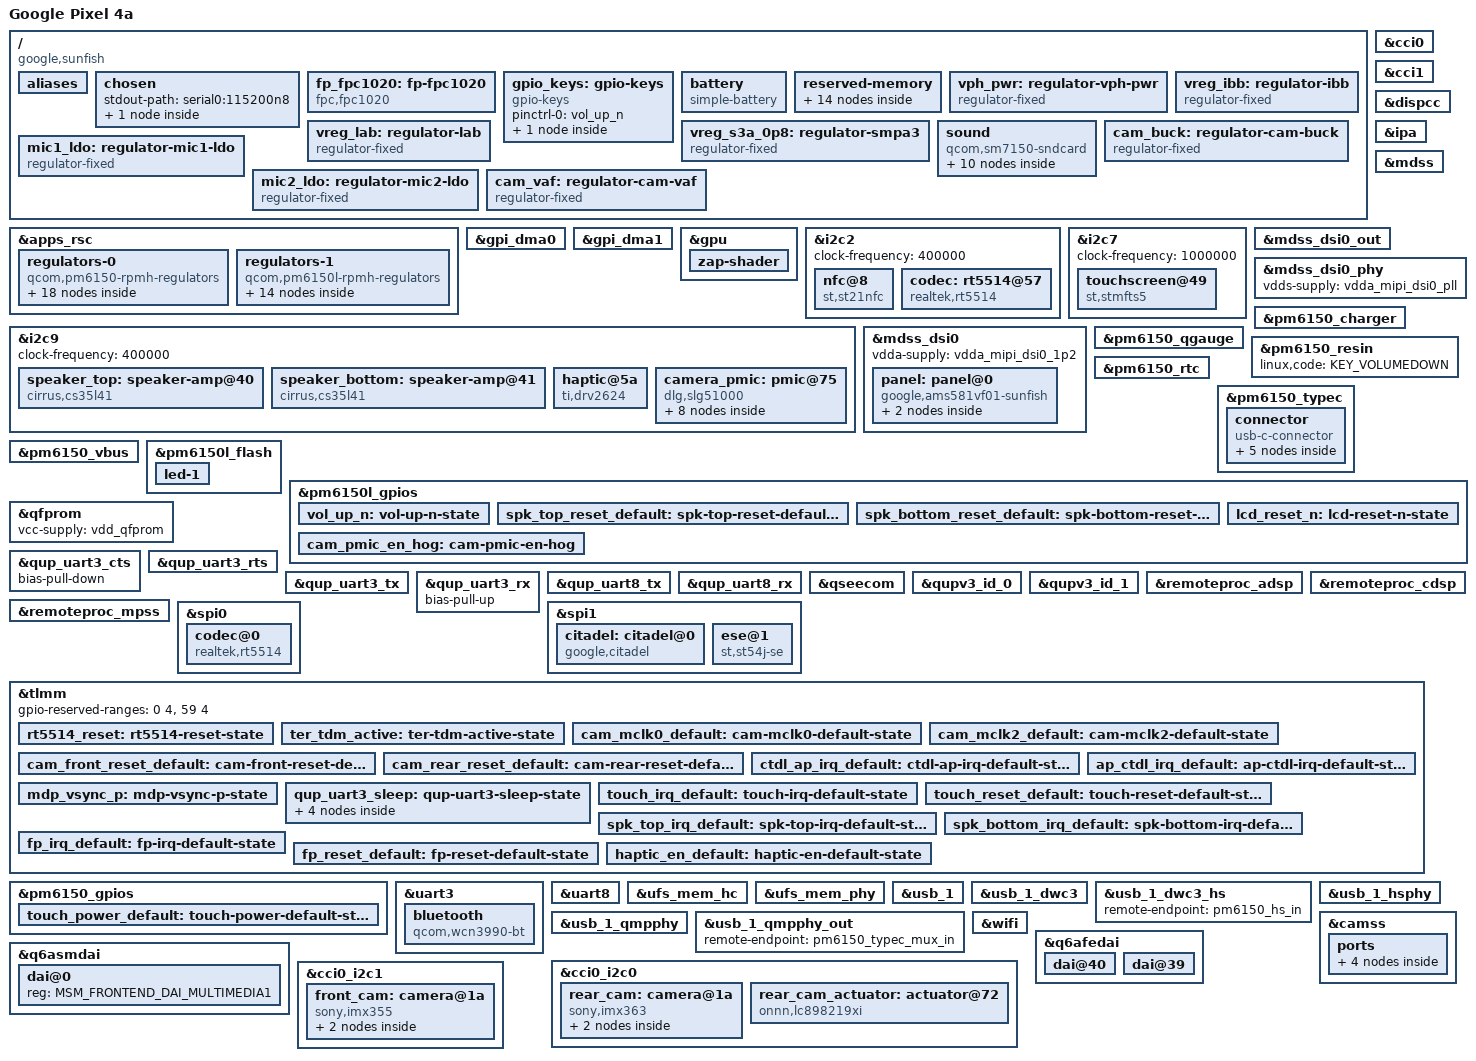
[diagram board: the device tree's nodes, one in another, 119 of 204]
// SPDX-License-Identifier: BSD-3-Clause
/*
 * Copyright (c) 2023-2024, Connor Mitchell <c.dog29@hotmail.com>
 * Copyright (c) 2025, Danila Tikhonov <danila@jiaxyga.com>
 */

/dts-v1/;

#include <dt-bindings/firmware/qcom,scm.h>
#include <dt-bindings/gpio/gpio.h>
#include <dt-bindings/leds/common.h>
#include <dt-bindings/pinctrl/qcom,pmic-gpio.h>
#include <dt-bindings/regulator/qcom,rpmh-regulator.h>
#include <dt-bindings/sound/qcom,q6afe.h>
#include <dt-bindings/sound/qcom,q6asm.h>
#include <dt-bindings/usb/pd.h>

#include "sm7150.dtsi"
#include "pm6150.dtsi"
#include "pm6150l.dtsi"

/delete-node/ &mpss_mem;
/delete-node/ &venus_mem;
/delete-node/ &cdsp_mem;
/delete-node/ &adsp_mem;
/delete-node/ &wlan_msa_mem;
/delete-node/ &npu_mem;
/delete-node/ &ipa_fw_mem;
/delete-node/ &ipa_gsi_mem;
/delete-node/ &gpu_mem;

/ {
	model = "Google Pixel 4a";
	compatible = "google,sunfish", "qcom,sm7150";
	chassis-type = "handset";

	aliases {
		bluetooth0 = &bluetooth;
		hsuart0 = &uart3;
		serial0 = &uart8;
		wifi0 = &wifi;
	};

	chosen {
		#address-cells = <2>;
		#size-cells = <2>;
		ranges;

		stdout-path = "serial0:115200n8";

		framebuffer@9c000000 {
			compatible = "simple-framebuffer";
			reg = <0x0 0x9c000000 0x0 (1080 * 2340 * 4)>;
			width = <1080>;
			height = <2340>;
			stride = <(1080 * 4)>;
			format = "a8r8g8b8";

			clocks = <&gcc GCC_DISP_HF_AXI_CLK>;
		};
	};

	/*
	 * The sensor's SPI bus belongs to the TrustZone fingerprint app;
	 * Linux only drives reset and forwards the interrupt. The vendor
	 * HAL finds the device by looking for "fpc1020" under
	 * /sys/bus/platform/devices, so keep that in the node name.
	 */
	fp_fpc1020: fp-fpc1020 {
		compatible = "fpc,fpc1020";

		irq-gpios = <&tlmm 90 GPIO_ACTIVE_HIGH>;
		reset-gpios = <&tlmm 91 GPIO_ACTIVE_LOW>;

		pinctrl-0 = <&fp_irq_default>, <&fp_reset_default>;
		pinctrl-names = "default";
	};

	gpio_keys: gpio-keys {
		compatible = "gpio-keys";

		pinctrl-0 = <&vol_up_n>;
		pinctrl-names = "default";

		key-volume-up {
			label = "Volume Up";
			gpios = <&pm6150l_gpios 2 GPIO_ACTIVE_LOW>;
			linux,code = <KEY_VOLUMEUP>;
			debounce-interval = <15>;
			linux,can-disable;
			wakeup-source;
		};
	};

	/*
	 * Values match Google's downstream sunfish ATL/LSN cell profiles
	 * (3080 mAh, 4.45 V max, 3.30 V min). The downstream kernel
	 * dynamically selects per-cell profiles via a battery-ID resistor;
	 * the DT-only path here picks the original pack data shared by
	 * both vendors. Phones whose LSN cells received the post-incident
	 * software mitigation (max charge limited to 3.95 V) will see
	 * qcom_qg's voltage-based SOC plateau well below 100 %.
	 */
	battery: battery {
		compatible = "simple-battery";
		voltage-min-design-microvolt = <3300000>;
		voltage-max-design-microvolt = <4450000>;
		charge-full-design-microamp-hours = <3080000>;
		/*
		 * Approximate cell + path resistance; the downstream fuel gauge
		 * measures ESR at runtime instead. Used to estimate the resting
		 * voltage for the OCV lookup while charging or under load.
		 */
		factory-internal-resistance-micro-ohms = <150000>;

		/*
		 * OCV -> state-of-charge tables from Google's downstream ATL
		 * QG profile (batterydata-qcom-s5-SWD-ATL.dtsi,
		 * qcom,pc-temp-v1-lut). The LSN profile differs by < 20 mV,
		 * so one set of tables serves both cell vendors.
		 */
		ocv-capacity-celsius = <0 10 25 40 50>;
		/* 0 degC */
		ocv-capacity-table-0 = <4419500 100>, <4396800 98>, <4373700 96>, <4350900 94>,
			<4327500 92>, <4303000 90>, <4278400 88>, <4253900 86>,
			<4229400 84>, <4205400 82>, <4181900 80>, <4158800 78>,
			<4136300 76>, <4114500 74>, <4093600 72>, <4073500 70>,
			<4053500 68>, <4032800 66>, <4012900 64>, <3996100 62>,
			<3981100 60>, <3965400 58>, <3948900 56>, <3931400 54>,
			<3910900 52>, <3889400 50>, <3873800 48>, <3862300 46>,
			<3853600 44>, <3847400 42>, <3842500 40>, <3837700 38>,
			<3833200 36>, <3829100 34>, <3825500 32>, <3822000 30>,
			<3818500 28>, <3815200 26>, <3810500 24>, <3802200 22>,
			<3791400 20>, <3779200 18>, <3764800 16>, <3748600 14>,
			<3732900 12>, <3721700 10>, <3717800 9>, <3714300 8>,
			<3711200 7>, <3707700 6>, <3693000 5>, <3652700 4>,
			<3595700 3>, <3516900 2>, <3382800 1>, <3000000 0>;
		/* 10 degC */
		ocv-capacity-table-1 = <4430200 100>, <4407100 98>, <4385500 96>, <4363200 94>,
			<4340800 92>, <4317400 90>, <4293000 88>, <4268400 86>,
			<4243700 84>, <4219100 82>, <4195000 80>, <4171200 78>,
			<4148100 76>, <4125600 74>, <4103800 72>, <4082800 70>,
			<4062600 68>, <4042800 66>, <4023600 64>, <4005200 62>,
			<3989000 60>, <3972200 58>, <3948500 56>, <3918500 54>,
			<3897600 52>, <3884700 50>, <3874400 48>, <3865300 46>,
			<3857500 44>, <3849800 42>, <3842600 40>, <3835900 38>,
			<3829900 36>, <3824500 34>, <3820000 32>, <3816000 30>,
			<3812100 28>, <3808600 26>, <3804000 24>, <3795700 22>,
			<3784000 20>, <3771500 18>, <3757400 16>, <3741000 14>,
			<3724800 12>, <3713700 10>, <3710700 9>, <3708700 8>,
			<3706400 7>, <3702900 6>, <3685100 5>, <3643200 4>,
			<3584800 3>, <3504200 2>, <3370300 1>, <3000000 0>;
		/* 25 degC */
		ocv-capacity-table-2 = <4437900 100>, <4412000 98>, <4390000 96>, <4368600 94>,
			<4346300 92>, <4323200 90>, <4299200 88>, <4274400 86>,
			<4249600 84>, <4224900 82>, <4200400 80>, <4176400 78>,
			<4152900 76>, <4129800 74>, <4107300 72>, <4085500 70>,
			<4064700 68>, <4044600 66>, <4025800 64>, <4007800 62>,
			<3990100 60>, <3973200 58>, <3953700 56>, <3926800 54>,
			<3902400 52>, <3888800 50>, <3878700 48>, <3868400 46>,
			<3858100 44>, <3848800 42>, <3840500 40>, <3833100 38>,
			<3826600 36>, <3820800 34>, <3815700 32>, <3811400 30>,
			<3806900 28>, <3802500 26>, <3797400 24>, <3789400 22>,
			<3778200 20>, <3766100 18>, <3752700 16>, <3736700 14>,
			<3719800 12>, <3709300 10>, <3706700 9>, <3705000 8>,
			<3703200 7>, <3699200 6>, <3679300 5>, <3636300 4>,
			<3578400 3>, <3499500 2>, <3377200 1>, <3000000 0>;
		/* 40 degC */
		ocv-capacity-table-3 = <4440600 100>, <4413900 98>, <4391100 96>, <4370100 94>,
			<4348200 92>, <4325900 90>, <4302700 88>, <4278600 86>,
			<4254100 84>, <4229400 82>, <4204700 80>, <4180600 78>,
			<4157000 76>, <4133700 74>, <4111000 72>, <4088900 70>,
			<4067700 68>, <4047300 66>, <4028000 64>, <4009600 62>,
			<3991600 60>, <3974400 58>, <3955700 56>, <3931500 54>,
			<3907600 52>, <3891600 50>, <3879300 48>, <3868000 46>,
			<3857300 44>, <3847400 42>, <3838400 40>, <3830200 38>,
			<3823000 36>, <3816500 34>, <3810700 32>, <3805700 30>,
			<3800400 28>, <3794400 26>, <3787500 24>, <3779100 22>,
			<3768800 20>, <3757300 18>, <3743900 16>, <3728300 14>,
			<3712200 12>, <3702900 10>, <3700600 9>, <3699100 8>,
			<3697300 7>, <3693200 6>, <3671500 5>, <3627800 4>,
			<3570400 3>, <3492300 2>, <3372300 1>, <3000000 0>;
		/* 50 degC */
		ocv-capacity-table-4 = <4441700 100>, <4413900 98>, <4391400 96>, <4370300 94>,
			<4349500 92>, <4327400 90>, <4304400 88>, <4280400 86>,
			<4256000 84>, <4231700 82>, <4207400 80>, <4183300 78>,
			<4159400 76>, <4135900 74>, <4113000 72>, <4090900 70>,
			<4069600 68>, <4049200 66>, <4029700 64>, <4011100 62>,
			<3992800 60>, <3975200 58>, <3956500 56>, <3933200 54>,
			<3909500 52>, <3892700 50>, <3879500 48>, <3867900 46>,
			<3857200 44>, <3847400 42>, <3838100 40>, <3829600 38>,
			<3821900 36>, <3814800 34>, <3808300 32>, <3802600 30>,
			<3796400 28>, <3788800 26>, <3780200 24>, <3771100 22>,
			<3761200 20>, <3749900 18>, <3736400 16>, <3721000 14>,
			<3705400 12>, <3696700 10>, <3694400 9>, <3692900 8>,
			<3691200 7>, <3686100 6>, <3662100 5>, <3617600 4>,
			<3560000 3>, <3481800 2>, <3360700 1>, <3000000 0>;
	};

	reserved-memory {
		mpss_mem: memory@8b000000 {
			reg = <0x0 0x8b000000 0x0 0x9800000>;
			no-map;
		};

		venus_mem: memory@94800000 {
			reg = <0x0 0x94800000 0x0 0x500000>;
			no-map;
		};

		cdsp_mem: memory@94d00000 {
			reg = <0x0 0x94d00000 0x0 0x1e00000>;
			no-map;
		};

		adsp_mem: memory@96b00000 {
			reg = <0x00 0x96b00000 0x00 0x2200000>;
			no-map;
		};

		wlan_msa_mem: memory@98d00000 {
			reg = <0x0 0x98d00000 0x0 0x200000>;
			no-map;
		};

		npu_mem: memory@98f00000 {
			reg = <0x0 0x98f00000 0x0 0x80000>;
			no-map;
		};

		ipa_fw_mem: memory@98f80000 {
			reg = <0x0 0x98f80000 0x0 0x10000>;
			no-map;
		};

		ipa_gsi_mem: memory@98f90000 {
			reg = <0x0 0x98f90000 0x0 0x5000>;
			no-map;
		};

		gpu_mem: memory@98f95000 {
			reg = <0x0 0x98f95000 0x0 0x2000>;
			no-map;
		};

		cont_splash_mem: cont-splash@9c000000 {
			reg = <0x0 0x9c000000 0x0 (1080 * 2340 * 4)>;
			no-map;
		};

		ramoops_mem: ramoops@a481f000 {
			compatible = "ramoops";
			reg = <0x0 0xa481f000 0x0 0x400000>;

			record-size = <0x40000>;
			console-size = <0x200000>;
			pmsg-size = <0x100000>;
		};

		rmtfs_mem: rmtfs@fde01000 {
			compatible = "qcom,rmtfs-mem";
			reg = <0x0 0xfde01000 0x0 0x600000>;
			no-map;

			qcom,client-id = <1>;
			qcom,vmid = <QCOM_SCM_VMID_MSS_MSA>;
		};

		/*
		 * rmtfs is 4K- but not 16K-aligned. With 16K pages the pages at
		 * either end would also hold ordinary RAM, so memremap() of
		 * rmtfs fails. Keep those slivers out of the linear map.
		 */
		rmtfs_pad_lo: memory@fde00000 {
			reg = <0x0 0xfde00000 0x0 0x1000>;
			no-map;
		};

		rmtfs_pad_hi: memory@fe401000 {
			reg = <0x0 0xfe401000 0x0 0x3000>;
			no-map;
		};
	};

	vph_pwr: regulator-vph-pwr {
		compatible = "regulator-fixed";

		regulator-name = "vph_pwr";
		regulator-min-microvolt = <3700000>;
		regulator-max-microvolt = <3700000>;

		regulator-always-on;
		regulator-boot-on;
	};

	vreg_ibb: regulator-ibb {
		compatible = "regulator-fixed";

		regulator-name = "ibb";
		regulator-min-microvolt = <6000000>;
		regulator-max-microvolt = <6000000>;
	};

	vreg_lab: regulator-lab {
		compatible = "regulator-fixed";

		regulator-name = "lab";
		regulator-min-microvolt = <6100000>;
		regulator-max-microvolt = <6100000>;
	};

	// S3A is really mx.lvl but it's there for supply map completeness sake.
	vreg_s3a_0p8: regulator-smpa3 {
		compatible = "regulator-fixed";

		regulator-name = "vreg_s3a_0p8";
		regulator-min-microvolt = <800000>;
		regulator-max-microvolt = <800000>;

		regulator-always-on;
		vin-supply = <&vph_pwr>;
	};
};

&apps_rsc {
	regulators-0 {
		compatible = "qcom,pm6150-rpmh-regulators";
		qcom,pmic-id = "a";

		vdd-s1-supply = <&vph_pwr>;
		vdd-s2-supply = <&vph_pwr>;
		vdd-s3-supply = <&vph_pwr>;
		vdd-s4-supply = <&vph_pwr>;
		vdd-s5-supply = <&vph_pwr>;

		vdd-l1-supply = <&vreg_s8c_1p2>;
		vdd-l2-l3-supply = <&vreg_s4a_1p1>;
		vdd-l4-l7-l8-supply = <&vreg_s4a_1p1>;
		vdd-l5-l16-l17-l18-l19-supply = <&vreg_bob>;
		vdd-l6-supply = <&vreg_s8c_1p2>;
		vdd-l9-supply = <&vreg_s3a_0p8>;
		vdd-l10-l14-l15-supply = <&vreg_s5a_2p0>;
		vdd-l11-l12-l13-supply = <&vreg_s5a_2p0>;

		/*
		 * S1, S4, S5 are unused.
		 * S2-S3 and L7-L8 are ARCs:
		 * S2 - gfx.lvl,
		 * S3 - mx.lvl,
		 * L7 - lmx.lvl,
		 * L8 - lcx.lvl.
		 */

		vreg_s4a_1p1: smps4 {
			regulator-name = "vreg_s4a_1p1";
			regulator-min-microvolt = <824000>;
			regulator-max-microvolt = <1120000>;
			regulator-initial-mode = <RPMH_REGULATOR_MODE_HPM>;
		};

		vreg_s5a_2p0: smps5 {
			regulator-name = "vreg_s5a_2p0";
			regulator-min-microvolt = <1744000>;
			regulator-max-microvolt = <2040000>;
			regulator-initial-mode = <RPMH_REGULATOR_MODE_HPM>;
		};

		vreg_l1a_1p2: ldo1 {
			regulator-name = "vreg_l1a_1p2";
			regulator-min-microvolt = <1096000>;
			regulator-max-microvolt = <1304000>;
			regulator-initial-mode = <RPMH_REGULATOR_MODE_HPM>;
		};

		vreg_l2a_1p0: ldo2 {
			regulator-name = "vreg_l2a_1p0";
			regulator-min-microvolt = <944000>;
			regulator-max-microvolt = <1056000>;
			regulator-initial-mode = <RPMH_REGULATOR_MODE_HPM>;
		};

		vdda_pll_cc_ebi01:
		vreg_l3a_1p0: ldo3 {
			regulator-name = "vreg_l3a_1p0";
			regulator-min-microvolt = <968000>;
			regulator-max-microvolt = <1064000>;
			regulator-initial-mode = <RPMH_REGULATOR_MODE_HPM>;
		};

		vdd_qlink_lv:
		vdd_qlink_lv_ck:
		vdd_usb_hs_core:
		vdda_mipi_csi0_0p9:
		vdda_mipi_csi1_0p9:
		vdda_mipi_csi2_0p9:
		vdda_mipi_csi3_0p9:
		vdda_mipi_dsi0_pll:
		vdda_qrefs_0p9:
		vdda_ufs_core:
		vdda_usb_ss_dp_core:
		vreg_l4a_0p88: ldo4 {
			regulator-name = "vreg_l4a_0p88";
			regulator-min-microvolt = <824000>;
			regulator-max-microvolt = <920000>;
			regulator-initial-mode = <RPMH_REGULATOR_MODE_HPM>;
			regulator-allow-set-load;
			regulator-allowed-modes = <RPMH_REGULATOR_MODE_LPM
						   RPMH_REGULATOR_MODE_HPM>;
		};

		vreg_l5a_2p7: ldo5 {
			regulator-name = "vreg_l5a_2p7";
			regulator-min-microvolt = <2600000>;
			regulator-max-microvolt = <2800000>;
			regulator-initial-mode = <RPMH_REGULATOR_MODE_HPM>;
		};

		vreg_l6a_1p2: ldo6 {
			regulator-name = "vreg_l6a_1p2";
			regulator-min-microvolt = <1096000>;
			regulator-max-microvolt = <1304000>;
			regulator-initial-mode = <RPMH_REGULATOR_MODE_HPM>;
		};

		vdd_wcss_cx:
		vreg_l9a_0p8: ldo9 {
			regulator-name = "vreg_l9a_0p8";
			regulator-min-microvolt = <624000>;
			regulator-max-microvolt = <760000>;
			regulator-initial-mode = <RPMH_REGULATOR_MODE_HPM>;
		};

		vddpx_3:
		vreg_l10a_1p8: ldo10 {
			regulator-name = "vreg_l10a_1p8";
			regulator-min-microvolt = <1720000>;
			regulator-max-microvolt = <1832000>;
			regulator-initial-mode = <RPMH_REGULATOR_MODE_HPM>;
		};

		vdd_qfprom:
		vdda_apc1_cs_1p8:
		vdda_qrefs_1p8:
		vdda_usb_hs_1p8:
		vddpx_11:
		vreg_l11a_1p8: ldo11 {
			regulator-name = "vreg_l11a_1p8";
			regulator-min-microvolt = <1696000>;
			regulator-max-microvolt = <1984000>;
			regulator-initial-mode = <RPMH_REGULATOR_MODE_HPM>;
		};

		vreg_l12a_1p8: ldo12 {
			regulator-name = "vreg_l12a_1p8";
			regulator-min-microvolt = <1696000>;
			regulator-max-microvolt = <1952000>;
			regulator-initial-mode = <RPMH_REGULATOR_MODE_HPM>;
			regulator-allow-set-load;
			regulator-allowed-modes = <RPMH_REGULATOR_MODE_LPM
						   RPMH_REGULATOR_MODE_HPM>;
		};

		vreg_l13a_1p8: ldo13 {
			regulator-name = "vreg_l13a_1p8";
			regulator-min-microvolt = <1696000>;
			regulator-max-microvolt = <1904000>;
			regulator-initial-mode = <RPMH_REGULATOR_MODE_HPM>;
		};

		vreg_l14a_1p8: ldo14 {
			regulator-name = "vreg_l14a_1p8";
			regulator-min-microvolt = <1720000>;
			regulator-max-microvolt = <1856000>;
			regulator-initial-mode = <RPMH_REGULATOR_MODE_HPM>;
		};

		vreg_l15a_1p8: ldo15 {
			regulator-name = "vreg_l15a_1p8";
			regulator-min-microvolt = <1696000>;
			regulator-max-microvolt = <1904000>;
			regulator-initial-mode = <RPMH_REGULATOR_MODE_HPM>;
		};

		vreg_l16a_2p8: ldo16 {
			regulator-name = "vreg_l16a_2p8";
			regulator-min-microvolt = <2424000>;
			regulator-max-microvolt = <2976000>;
			regulator-initial-mode = <RPMH_REGULATOR_MODE_HPM>;
		};

		vdda_usb_hs_3p1:
		vreg_l17a_3p1: ldo17 {
			regulator-name = "vreg_l17a_3p1";
			regulator-min-microvolt = <3000000>;
			regulator-max-microvolt = <3232000>;
			regulator-initial-mode = <RPMH_REGULATOR_MODE_HPM>;
		};

		vreg_l19a_2p85: ldo19 {
			regulator-name = "vreg_l19a_2p85";
			regulator-min-microvolt = <2944000>;
			regulator-max-microvolt = <3304000>;
			regulator-initial-mode = <RPMH_REGULATOR_MODE_HPM>;
			regulator-allow-set-load;
			regulator-allowed-modes = <RPMH_REGULATOR_MODE_LPM
						   RPMH_REGULATOR_MODE_HPM>;
		};
	};

	regulators-1 {
		compatible = "qcom,pm6150l-rpmh-regulators";
		qcom,pmic-id = "c";

		vdd-s1-supply = <&vph_pwr>;
		vdd-s2-supply = <&vph_pwr>;
		vdd-s3-supply = <&vph_pwr>;
		vdd-s4-supply = <&vph_pwr>;
		vdd-s5-supply = <&vph_pwr>;
		vdd-s6-supply = <&vph_pwr>;
		vdd-s7-supply = <&vph_pwr>;
		vdd-s8-supply = <&vph_pwr>;

		vdd-l2-l3-supply = <&vreg_s8c_1p2>;
		vdd-l4-l5-l6-supply = <&vreg_bob>;
		vdd-l7-l11-supply = <&vreg_bob>;
		vdd-l9-l10-supply = <&vreg_bob>;

		vdd-bob-supply = <&vph_pwr>;
		vdd-flash-supply = <&vreg_bob>;
		vdd-rgb-supply = <&vreg_bob>;

		/*
		 * S4, S5 are unused.
		 * S2, S3, S7 are ARCs:
		 * S2-S3 - cx.lvl,
		 * S7 - mss.lvl.
		 */

		vreg_s1c_1p13: smps1 {
			regulator-name = "vreg_s1c_1p13";
			regulator-min-microvolt = <1000000>;
			regulator-max-microvolt = <1200000>;
			regulator-initial-mode = <RPMH_REGULATOR_MODE_HPM>;
		};

		vreg_s8c_1p2: smps8 {
			regulator-name = "vreg_s8c_1p2";
			regulator-min-microvolt = <1200000>;
			regulator-max-microvolt = <1730000>;
			regulator-initial-mode = <RPMH_REGULATOR_MODE_HPM>;
		};

		vreg_l1c_1p8: ldo1 {
			regulator-name = "vreg_l1c_1p8";
			regulator-min-microvolt = <1616000>;
			regulator-max-microvolt = <1984000>;
			regulator-initial-mode = <RPMH_REGULATOR_MODE_HPM>;
		};

		vdd_wcss_adc_dac:
		vreg_l2c_1p3: ldo2 {
			regulator-name = "vreg_l2c_1p3";
			regulator-min-microvolt = <1200000>;
			regulator-max-microvolt = <1352000>;
			regulator-initial-mode = <RPMH_REGULATOR_MODE_HPM>;
		};

		vdda_csi0_1p25:
		vdda_csi1_1p25:
		vdda_csi2_1p25:
		vdda_csi3_1p25:
		vdda_hv_ebi0:
		vdda_mipi_dsi0_1p2:
		vdda_ufs_1p2:
		vdda_usb_ss_dp_1p2:
		vddpx_10:
		vreg_l3c_1p23: ldo3 {
			regulator-name = "vreg_l3c_1p23";
			regulator-min-microvolt = <1144000>;
			regulator-max-microvolt = <1256000>;
			regulator-initial-mode = <RPMH_REGULATOR_MODE_HPM>;
			regulator-allow-set-load;
			regulator-allowed-modes = <RPMH_REGULATOR_MODE_LPM
						   RPMH_REGULATOR_MODE_HPM>;
		};

		vddpx_5:
		vreg_l4c_1p8: ldo4 {
			regulator-name = "vreg_l4c_1p8";
			regulator-min-microvolt = <1648000>;
			regulator-max-microvolt = <2950000>;
			regulator-initial-mode = <RPMH_REGULATOR_MODE_HPM>;
		};

		vddpx_6:
		vreg_l5c_1p8: ldo5 {
			regulator-name = "vreg_l5c_1p8";
			regulator-min-microvolt = <1648000>;
			regulator-max-microvolt = <2950000>;
			regulator-initial-mode = <RPMH_REGULATOR_MODE_HPM>;
		};

		vddpx_2:
		vreg_l6c_3p0: ldo6 {
			regulator-name = "vreg_l6c_3p0";
			regulator-min-microvolt = <2960000>;
			regulator-max-microvolt = <3304000>;
			regulator-initial-mode = <RPMH_REGULATOR_MODE_HPM>;
		};

		vreg_l7c_3p0: ldo7 {
			regulator-name = "vreg_l7c_3p0";
			regulator-min-microvolt = <3000000>;
			regulator-max-microvolt = <3312000>;
			regulator-initial-mode = <RPMH_REGULATOR_MODE_HPM>;
		};

		vreg_l8c_1p8: ldo8 {
			regulator-name = "vreg_l8c_1p8";
			regulator-min-microvolt = <1800000>;
			regulator-max-microvolt = <1900000>;
			regulator-initial-mode = <RPMH_REGULATOR_MODE_HPM>;
		};

		vreg_l9c_3p1: ldo9 {
			regulator-name = "vreg_l9c_3p1";
			regulator-min-microvolt = <2950000>;
			regulator-max-microvolt = <3312000>;
			regulator-initial-mode = <RPMH_REGULATOR_MODE_HPM>;
		};

		vreg_l10c_3p3: ldo10 {
			regulator-name = "vreg_l10c_3p3";
			regulator-min-microvolt = <3200000>;
			regulator-max-microvolt = <3312000>;
			regulator-initial-mode = <RPMH_REGULATOR_MODE_HPM>;
		};

		vreg_l11c_3p3: ldo11 {
			regulator-name = "vreg_l11c_3p3";
			regulator-min-microvolt = <2950000>;
			regulator-max-microvolt = <3400000>;
			regulator-initial-mode = <RPMH_REGULATOR_MODE_HPM>;
		};

		vreg_bob: bob {
			regulator-name = "vreg_bob";
			regulator-min-microvolt = <3296000>;
			regulator-max-microvolt = <3960000>;
			regulator-initial-mode = <RPMH_REGULATOR_MODE_AUTO>;
			regulator-allow-bypass;
		};
	};
};

&cci0 {
	status = "okay";
};

&cci1 {
	status = "okay";
};

&dispcc {
	status = "okay";
};

&gpi_dma0 {
	status = "okay";
};

&gpi_dma1 {
	status = "okay";
};

&gpu {
	zap-shader {
		firmware-name = "qcom/sm7150/google/sunfish/a615_zap.mbn";
	};
};

&i2c2 {
	status = "okay";
	clock-frequency = <400000>;

	/*
	 * ST21NFCD, driven from userspace by the Android ST NFC HAL through
	 * /dev/st21nfc. GPIOs as in downstream sm7150-sunfish-nfc.dtsi.
	 */
	nfc@8 {
		compatible = "st,st21nfc";
		reg = <0x08>;

		interrupts-extended = <&tlmm 37 IRQ_TYPE_EDGE_RISING>;

		irq-gpios = <&tlmm 37 GPIO_ACTIVE_HIGH>;
		reset-gpios = <&tlmm 67 GPIO_ACTIVE_HIGH>;
		pidle-gpios = <&tlmm 94 GPIO_ACTIVE_HIGH>;
		clkreq-gpios = <&tlmm 31 GPIO_ACTIVE_HIGH>;
		st,clk_pinctrl;
	};

	codec: rt5514@57 {
		compatible = "realtek,rt5514";
		reg = <0x57>;
		#sound-dai-cells = <0>;

		/* reset is active low; stock just holds it released */
		pinctrl-0 = <&rt5514_reset>;
		pinctrl-names = "default";
	};
};

&i2c7 {
	status = "okay";
	clock-frequency = <1000000>;

	touchscreen@49 {
		compatible = "st,stmfts5";
		reg = <0x49>;

		interrupts-extended = <&tlmm 9 IRQ_TYPE_LEVEL_LOW>;
		reset-gpios = <&tlmm 8 GPIO_ACTIVE_LOW>;

		/*
		 * The FTM5 touch IC is in-cell: it lives inside the OLED panel
		 * module and is powered through the panel's own rails, so the
		 * driver follows the panel's prepare/unprepare to power it.
		 */
		panel = <&panel>;

		/*
		 * GPIO 72 routes the touch IRQ between the AP (active-low)
		 * and SLPI (active-high). Mainline only services the AP path,
		 * so the driver holds this deasserted (low) by default.
		 */
		mode-switch-gpios = <&tlmm 72 GPIO_ACTIVE_LOW>;

		/*
		 * VDD (digital, 1.8V) and AVDD (analog, 3.0V) are separate
		 * physical supplies on the chip.  Downstream Android documents
		 * the mapping in a commented-out hint in its sunfish DT, and
		 * the rails are shared with the OLED panel (touch and display
		 * are one bonded assembly).  pm6150 GPIO 4 enables an external
		 * load switch upstream of these rails; it is asserted via
		 * pinctrl below.
		 */
		vdd-supply  = <&vreg_l13a_1p8>;	/* 1.8V digital, shared with display vddio */
		avdd-supply = <&vreg_l7c_3p0>;	/* 3.0V analog,  shared with display vdda-3p3 */

		touchscreen-size-x = <1080>;
		touchscreen-size-y = <2340>;

		pinctrl-names = "default";
		pinctrl-0 = <&touch_irq_default &touch_reset_default &touch_power_default>;
	};
};

&i2c9 {
	status= "okay";
	clock-frequency = <400000>;

	/* microchip,pac1934 power-monitor@10 */
	/*
	 * Top (earpiece/left) and bottom (loudspeaker/right) CS35L41 smart
	 * amps, fed by the ADSP over secondary TDM. Values follow the
	 * downstream sm7150-sunfish-audio.dtsi: internal boost, IRQ routed
	 * out on GPIO2 as push-pull active-high.
	 */
	speaker_top: speaker-amp@40 {
		compatible = "cirrus,cs35l41";
		reg = <0x40>;
		#sound-dai-cells = <1>;
		sound-name-prefix = "L";
		cirrus,subsystem-id = "sunfish";

		reset-gpios = <&pm6150l_gpios 8 GPIO_ACTIVE_HIGH>;
		interrupts-extended = <&tlmm 64 IRQ_TYPE_LEVEL_HIGH>;

		pinctrl-0 = <&spk_top_reset_default>, <&spk_top_irq_default>;
		pinctrl-names = "default";

		cirrus,boost-type = <0>;
		cirrus,boost-peak-milliamp = <3700>;
		cirrus,boost-ind-nanohenry = <1000>;
		cirrus,boost-cap-microfarad = <15>;
		cirrus,asp-sdout-hiz = <3>;
		cirrus,gpio2-src-select = <5>;
		cirrus,gpio2-output-enable;
	};

	speaker_bottom: speaker-amp@41 {
		compatible = "cirrus,cs35l41";
		reg = <0x41>;
		#sound-dai-cells = <1>;
		sound-name-prefix = "R";
		cirrus,subsystem-id = "sunfish";

		reset-gpios = <&pm6150l_gpios 11 GPIO_ACTIVE_HIGH>;
		interrupts-extended = <&tlmm 65 IRQ_TYPE_LEVEL_HIGH>;

		pinctrl-0 = <&spk_bottom_reset_default>, <&spk_bottom_irq_default>;
		pinctrl-names = "default";

		cirrus,boost-type = <0>;
		cirrus,boost-peak-milliamp = <3700>;
		cirrus,boost-ind-nanohenry = <1000>;
		cirrus,boost-cap-microfarad = <15>;
		cirrus,asp-sdout-hiz = <3>;
		cirrus,gpio2-src-select = <5>;
		cirrus,gpio2-output-enable;
	};

	/*
	typec-mux@43 {
		compatible = "fcs,fsa4480";
		reg = <0x43>;

		interrupts-extended = <&tlmm 42 IRQ_TYPE_LEVEL_LOW>;

		vcc-supply = <&vreg_bob>;

		mode-switch;
		orientation-switch;

		port {
			fsa4480_sbu_mux: endpoint {
				remote-endpoint = <&pm6150_typec_sbu_out>;
			};
		};
	};
	*/

	/* st,m24c08 e2prom@50 */

	haptic@5a {
		compatible = "ti,drv2624";
		reg = <0x5a>;

		enable-gpios = <&tlmm 11 GPIO_ACTIVE_HIGH>;

		ti,actuator = "lra";
		ti,lra-frequency-hz = <172>;

		/* Tone down the LRA: overdrive clamp lowered from the 0x89
		 * (~4 Vpk) chip default to ~2.8 Vpk so haptics aren't harsh. */
		ti,od-clamp-reg = <0x60>;

		/* Factory autocal from a real sunfish
		 * /persist/haptics/drv2624.cal (shared default). */
		ti,autocal-comp = /bits/ 8 <18 150 0>;

		/* Open loop off resonance, as stock (ti,smart-loop = <1>,
		 * ti,ol-lra-frequency = <155>): 1e9 / (24615 * 155) = 262.
		 * Closed loop at f0 drives the LRA noticeably harder. */
		ti,open-loop;
		ti,ol-lra-period = <262>;

		pinctrl-names = "default";
		pinctrl-0 = <&haptic_en_default>;
	};

	/*
	 * Dialog SLG51000 camera PMIC. Downstream raises the camera buck
	 * (cam_buck), then this chip's CS pin, and holds pm6150l GPIOs 1/5
	 * low (cam_pmic_en_hog). Rails as used by the rear IMX363.
	 */
	camera_pmic: pmic@75 {
		compatible = "dlg,slg51000";
		reg = <0x75>;

		dlg,cs-gpios = <&pm6150l_gpios 4 GPIO_ACTIVE_HIGH>;

		vin3-supply = <&cam_buck>;
		vin4-supply = <&cam_buck>;
		vin5-supply = <&cam_buck>;
		vin6-supply = <&cam_buck>;
		vin7-supply = <&cam_buck>;

		regulators {
			slg51000_ldo1: ldo1 {
				regulator-name = "slg51000_ldo1";
				regulator-min-microvolt = <2850000>;
				regulator-max-microvolt = <2850000>;
				/* needed for the rear IMX363 to answer on CCI (as stock) */
				regulator-always-on;
			};

			slg51000_ldo2: ldo2 {
				regulator-name = "slg51000_ldo2";
				regulator-min-microvolt = <2800000>;
				regulator-max-microvolt = <2800000>;
			};

			slg51000_ldo3: ldo3 {
				regulator-name = "slg51000_ldo3";
				regulator-min-microvolt = <2850000>;
				regulator-max-microvolt = <2850000>;
			};

			slg51000_ldo4: ldo4 {
				regulator-name = "slg51000_ldo4";
				regulator-min-microvolt = <1800000>;
				regulator-max-microvolt = <1800000>;
				/* needed for the rear IMX363 to answer on CCI (as stock) */
				regulator-always-on;
			};

			slg51000_ldo5: ldo5 {
				regulator-name = "slg51000_ldo5";
				regulator-min-microvolt = <1200000>;
				regulator-max-microvolt = <1200000>;
			};

			slg51000_ldo6: ldo6 {
				regulator-name = "slg51000_ldo6";
				regulator-min-microvolt = <1050000>;
				regulator-max-microvolt = <1050000>;
			};

			slg51000_ldo7: ldo7 {
				regulator-name = "slg51000_ldo7";
				regulator-min-microvolt = <1800000>;
				regulator-max-microvolt = <1800000>;
			};
		};
	};
};

&ipa {
	memory-region = <&ipa_fw_mem>;
	firmware-name = "qcom/sm7150/google/sunfish/ipa_fws.mbn";
	status = "okay";
};

&mdss {
	status = "okay";
};

&mdss_dsi0 {
	vdda-supply = <&vdda_mipi_dsi0_1p2>;
	status = "okay";

	panel: panel@0 {
		compatible = "google,ams581vf01-sunfish",
			     "samsung,ams581vf01";
		reg = <0>;

		vddio-supply = <&vreg_l13a_1p8>;
		vdd3p3-supply = <&vreg_l7c_3p0>;
		vsn-supply = <&vreg_ibb>;
		vsp-supply = <&vreg_lab>;

		reset-gpios = <&pm6150l_gpios 9 GPIO_ACTIVE_LOW>;

		pinctrl-0 = <&lcd_reset_n>,
			    <&mdp_vsync_p>;
		pinctrl-names = "default";

		port {
			panel_in: endpoint {
				remote-endpoint = <&mdss_dsi0_out>;
			};
		};
	};
};

&mdss_dsi0_out {
	data-lanes = <0 1 2 3>;
	remote-endpoint = <&panel_in>;
	status = "okay";
};

&mdss_dsi0_phy {
	vdds-supply = <&vdda_mipi_dsi0_pll>;
	status = "okay";
};

&pm6150_charger {
	monitored-battery = <&battery>;
	/* Type-C Rp / PD contract current from the TCPM port */
	power-supplies = <&pm6150_typec>;
	status = "okay";
};

&pm6150_qgauge {
	monitored-battery = <&battery>;
	power-supplies = <&pm6150_charger>;
	status = "okay";
};

&pm6150_resin {
	linux,code = <KEY_VOLUMEDOWN>;
	status = "okay";
};

&pm6150_rtc {
	status = "okay";
};

&pm6150_typec {
	vdd-vbus-supply = <&pm6150_vbus>;
	vdd-pdphy-supply = <&vdda_usb_hs_3p1>;
	status = "okay";

	connector {
		compatible = "usb-c-connector";

		op-sink-microwatt = <10000000>;
		power-role = "dual";
		data-role = "dual";
		self-powered;

		source-pdos = <PDO_FIXED(5000, 3000, PDO_FIXED_DUAL_ROLE |
			       PDO_FIXED_USB_COMM | PDO_FIXED_DATA_SWAP)>;

		sink-pdos = <PDO_FIXED(5000, 3000, PDO_FIXED_DUAL_ROLE |
			     PDO_FIXED_USB_COMM | PDO_FIXED_DATA_SWAP)
			     PDO_VAR(5000, 9000, 3000)>;

		ports {
			#address-cells = <1>;
			#size-cells = <0>;

			port@0 {
				reg = <0>;
				pm6150_hs_in: endpoint {
					remote-endpoint = <&usb_1_dwc3_hs>;
				};
			};


			port@1 {
				reg = <1>;
				pm6150_typec_mux_in: endpoint {
					remote-endpoint = <&usb_1_qmpphy_out>;
				};
			};

			/* TODO: Investigate, I don't think fsa4480 exists
			port@2 {
				reg = <2>;
				pm6150_typec_sbu_out: endpoint {
					remote-endpoint = <&fsa4480_sbu_mux>;
				};
			};
			*/
		};
	};
};

&pm6150_vbus {
	regulator-min-microamp = <500000>;
	regulator-max-microamp = <3000000>;
	status = "okay";
};

&pm6150l_flash {
	status = "okay";

	led-1 {
		function = LED_FUNCTION_FLASH;
		color = <LED_COLOR_ID_WHITE>;
		led-sources = <1>;
		led-max-microamp = <150000>;
		flash-max-microamp = <1000000>;
		flash-max-timeout-us = <1280000>;
	};
};

&pm6150l_gpios {
	vol_up_n: vol-up-n-state {
		pins = "gpio2";
		function = PMIC_GPIO_FUNC_NORMAL;
		input-enable;
		bias-pull-up;
		power-source = <0>;
	};

	spk_top_reset_default: spk-top-reset-default-state {
		pins = "gpio8";
		function = PMIC_GPIO_FUNC_NORMAL;
		qcom,drive-strength = <PMIC_GPIO_STRENGTH_LOW>;
		output-high;
		power-source = <1>;
	};

	spk_bottom_reset_default: spk-bottom-reset-default-state {
		pins = "gpio11";
		function = PMIC_GPIO_FUNC_NORMAL;
		qcom,drive-strength = <PMIC_GPIO_STRENGTH_LOW>;
		output-high;
		power-source = <1>;
	};

	lcd_reset_n: lcd-reset-n-state {
		pins = "gpio9";
		function = PMIC_GPIO_FUNC_FUNC1;
		qcom,drive-strength = <PMIC_GPIO_STRENGTH_MED>;
		bias-disable;
		output-low;
		power-source = <1>;
	};
};

&qfprom {
	vcc-supply = <&vdd_qfprom>;
};

&qup_uart3_cts {
	bias-pull-down;
};

&qup_uart3_rts {
	drive-strength = <2>;
	bias-disable;
};

&qup_uart3_tx {
	drive-strength = <2>;
	bias-disable;
};

&qup_uart3_rx {
	bias-pull-up;
};

&qup_uart8_tx {
	drive-strength = <2>;
	bias-disable;
};

&qup_uart8_rx {
	drive-strength = <2>;
	bias-pull-up;
};

&qseecom {
	status = "okay";
};

&qupv3_id_0 {
	status = "okay";
};

&qupv3_id_1 {
	status = "okay";
};

&remoteproc_adsp {
	firmware-name = "qcom/sm7150/google/sunfish/adsp.mbn";
	status = "okay";
};

&remoteproc_cdsp {
	firmware-name = "qcom/sm7150/google/sunfish/cdsp.mbn";
	status = "okay";
};

&remoteproc_mpss {
	firmware-name = "qcom/sm7150/google/sunfish/modem.mbn";
	status = "okay";
};

&spi0 {
	status = "okay";

	/* RT5514P DSP side: firmware download and its mic buffer (stock mnh-spi@0) */
	codec@0 {
		compatible = "realtek,rt5514";
		reg = <0>;
		spi-max-frequency = <10000000>;
		spi-cpol;
		spi-cpha;
	};
};

&spi1 {
	/*
	 * The Titan M SPI lines (gpio0-3) are muxed by the bootloader and
	 * locked down; downstream deliberately gives this SE an empty
	 * pinctrl. Do the same and keep the kernel away from those pins.
	 */
	/delete-property/ pinctrl-0;
	/delete-property/ pinctrl-names;
	status = "okay";

	citadel: citadel@0 {
		compatible = "google,citadel";
		reg = <0>;
		spi-max-frequency = <1200000>;

		ctdl-ap-irq-gpios = <&tlmm 4 GPIO_ACTIVE_HIGH>;
		ctdl-rst-gpios = <&tlmm 25 GPIO_ACTIVE_HIGH>;

		pinctrl-0 = <&ctdl_ap_irq_default>, <&ap_ctdl_irq_default>;
		pinctrl-names = "default";
	};

	/*
	 * ST54J eSE on CS1, used by the secure_element HAL through
	 * /dev/st54j_se. Downstream asks the SE for 90 SCLK cycles between
	 * CS and the first clock (11.25 us at 8 MHz).
	 */
	ese@1 {
		compatible = "st,st54j-se";
		reg = <1>;
		spi-max-frequency = <8000000>;
		spi-cs-setup-delay-ns = <11250>;

		reset-gpios = <&tlmm 63 GPIO_ACTIVE_LOW>;
	};
};

&tlmm {
	gpio-reserved-ranges = <0 4>, <59 4>;

	rt5514_reset: rt5514-reset-state {
		pins = "gpio33";
		function = "gpio";
		drive-strength = <2>;
		bias-disable;
		output-high;
	};

	/* RT5514 mic codec link (stock ter_tdm_*_active) */
	ter_tdm_active: ter-tdm-active-state {
		pins = "gpio53", "gpio54", "gpio55", "gpio56";
		function = "ter_mi2s";
		drive-strength = <8>;
		bias-disable;
	};

	cam_mclk0_default: cam-mclk0-default-state {
		pins = "gpio13";
		function = "cam_mclk";
		drive-strength = <2>;
		bias-disable;
	};

	cam_mclk2_default: cam-mclk2-default-state {
		pins = "gpio15";
		function = "cam_mclk";
		drive-strength = <2>;
		bias-disable;
	};

	cam_front_reset_default: cam-front-reset-default-state {
		pins = "gpio68";
		function = "gpio";
		drive-strength = <2>;
		bias-disable;
	};

	cam_rear_reset_default: cam-rear-reset-default-state {
		pins = "gpio43";
		function = "gpio";
		drive-strength = <2>;
		bias-disable;
	};

	ctdl_ap_irq_default: ctdl-ap-irq-default-state {
		pins = "gpio4";
		function = "gpio";
		drive-strength = <2>;
		bias-disable;
	};

	ap_ctdl_irq_default: ap-ctdl-irq-default-state {
		pins = "gpio16";
		function = "gpio";
		drive-strength = <2>;
		bias-pull-down;
		output-high;
	};

	mdp_vsync_p: mdp-vsync-p-state {
		pins = "gpio10";
		function = "mdp_vsync";
		drive-strength = <2>;
		bias-pull-down;
	};

	qup_uart3_sleep: qup-uart3-sleep-state {
		cts-pins {
			pins = "gpio38";
			function = "gpio";
			bias-pull-down;
		};

		rts-pins {
			pins = "gpio39";
			function = "gpio";
			bias-pull-down;
		};

		tx-pins {
			pins = "gpio40";
			function = "gpio";
			bias-pull-up;
		};

		rx-pins {
			pins = "gpio41";
			function = "gpio";
			bias-pull-up;
		};
	};

	touch_irq_default: touch-irq-default-state {
		pins = "gpio9";
		function = "gpio";
		drive-strength = <2>;
		bias-disable;
	};

	touch_reset_default: touch-reset-default-state {
		pins = "gpio8";
		function = "gpio";
		drive-strength = <2>;
		bias-pull-up;
		output-high;
	};

	spk_top_irq_default: spk-top-irq-default-state {
		pins = "gpio64";
		function = "gpio";
		drive-strength = <2>;
		bias-pull-down;
	};

	spk_bottom_irq_default: spk-bottom-irq-default-state {
		pins = "gpio65";
		function = "gpio";
		drive-strength = <2>;
		bias-pull-down;
	};

	fp_irq_default: fp-irq-default-state {
		pins = "gpio90";
		function = "gpio";
		drive-strength = <2>;
		bias-pull-down;
	};

	fp_reset_default: fp-reset-default-state {
		pins = "gpio91";
		function = "gpio";
		drive-strength = <2>;
		bias-disable;
	};

	haptic_en_default: haptic-en-default-state {
		pins = "gpio11";
		function = "gpio";
		drive-strength = <2>;
		bias-disable;
	};
};

&pm6150_gpios {
	touch_power_default: touch-power-default-state {
		pins = "gpio4";
		function = "normal";
		qcom,drive-strength = <2>;
		power-source = <1>;
		bias-disable;
		output-high;
	};
};

&uart3 {
	/delete-property/interrupts;
	interrupts-extended = <&intc GIC_SPI 604 IRQ_TYPE_LEVEL_HIGH>,
			      <&tlmm 41 IRQ_TYPE_EDGE_FALLING>;

	pinctrl-1 = <&qup_uart3_sleep>;
	pinctrl-names = "default",
			"sleep";

	status = "okay";

	bluetooth: bluetooth {
		compatible = "qcom,wcn3990-bt";

		vddio-supply = <&vreg_l10a_1p8>;
		vddxo-supply = <&vreg_l1c_1p8>;
		vddrf-supply = <&vdd_wcss_adc_dac>;
		vddch0-supply = <&vreg_l10c_3p3>;
		max-speed = <3200000>;
	};
};

&uart8 {
	status = "okay";
};

&ufs_mem_hc {
	reset-gpios = <&tlmm 119 GPIO_ACTIVE_LOW>;

	vcc-supply = <&vreg_l19a_2p85>;
	vcc-max-microamp = <600000>;
	vccq2-supply = <&vreg_l12a_1p8>;
	vccq2-max-microamp = <600000>;
	status = "okay";
};

&ufs_mem_phy {
	vdda-phy-supply = <&vdda_ufs_core>;
	vdda-pll-supply = <&vdda_ufs_1p2>;
	status = "okay";
};

&usb_1 {
	status = "okay";
};

&usb_1_dwc3 {
	dr_mode = "otg";
	usb-role-switch;
};

&usb_1_dwc3_hs {
	remote-endpoint = <&pm6150_hs_in>;
};

&usb_1_hsphy {
	vdd-supply = <&vdd_usb_hs_core>;
	vdda-pll-supply = <&vdda_usb_hs_1p8>;
	vdda-phy-dpdm-supply = <&vdda_usb_hs_3p1>;
	status = "okay";
};

&usb_1_qmpphy {
	vdda-pll-supply = <&vdda_usb_ss_dp_1p2>;
	vdda-phy-supply = <&vdda_usb_ss_dp_core>;
	orientation-switch;
	status = "okay";
};

&usb_1_qmpphy_out {
	remote-endpoint = <&pm6150_typec_mux_in>;
};

&wifi {
	vdd-0.8-cx-mx-supply = <&vdd_wcss_cx>;
	vdd-1.8-xo-supply = <&vreg_l1c_1p8>;
	vdd-1.3-rfa-supply = <&vdd_wcss_adc_dac>;
	vdd-3.3-ch0-supply = <&vreg_l10c_3p3>;
	vdd-3.3-ch1-supply = <&vreg_l11c_3p3>;

	qcom,ath10k-calibration-variant = "google_sunfish";

	status = "okay";
};

&q6afedai {
	/* CS35L41 speaker amps; matches downstream sunfish tdm_sec_rx */
	dai@40 {
		reg = <SECONDARY_TDM_RX_0>;
		qcom,tdm-sync-mode = <0>;
		qcom,tdm-sync-src = <1>;
		qcom,tdm-data-out = <0>;
		qcom,tdm-invert-sync = <0>;
		qcom,tdm-data-delay = <1>;
		qcom,tdm-data-align = <0>;
	};

	/* RT5514 mic codec; matches downstream sunfish tdm_tert_tx */
	dai@39 {
		reg = <TERTIARY_TDM_TX_0>;
		qcom,tdm-sync-mode = <0>;
		qcom,tdm-sync-src = <1>;
		qcom,tdm-data-out = <0>;
		qcom,tdm-invert-sync = <0>;
		qcom,tdm-data-delay = <1>;
		qcom,tdm-data-align = <0>;
	};
};

&q6asmdai {
	dai@0 {
		reg = <MSM_FRONTEND_DAI_MULTIMEDIA1>;
	};
};

/ {
	sound {
		compatible = "qcom,sm7150-sndcard";
		model = "Google Pixel 4a";

		pinctrl-0 = <&sec_tdm_active>, <&ter_tdm_active>;
		pinctrl-names = "default";

		mic1-ldo-supply = <&mic1_ldo>;
		mic2-ldo-supply = <&mic2_ldo>;

		audio-routing = "Left Spk", "L SPK",
				"Right Spk", "R SPK",
				"DMIC1L", "mic1-ldo",
				"DMIC1R", "mic1-ldo",
				"DMIC2L", "mic2-ldo",
				"DMIC2R", "mic2-ldo";

		mm1-dai-link {
			link-name = "MultiMedia1";

			cpu {
				sound-dai = <&q6asmdai MSM_FRONTEND_DAI_MULTIMEDIA1>;
			};
		};

		speaker-dai-link {
			link-name = "Speaker Playback";

			cpu {
				sound-dai = <&q6afedai SECONDARY_TDM_RX_0>;
			};

			platform {
				sound-dai = <&q6routing>;
			};

			codec {
				sound-dai = <&speaker_top 0>, <&speaker_bottom 0>;
			};
		};

		mic-dai-link {
			link-name = "Mic Capture";

			cpu {
				sound-dai = <&q6afedai TERTIARY_TDM_TX_0>;
			};

			platform {
				sound-dai = <&q6routing>;
			};

			codec {
				sound-dai = <&codec>;
			};
		};
	};
};

/ {
	/* Camera buck feeding the SLG51000; 5 ms settle as downstream */
	cam_buck: regulator-cam-buck {
		compatible = "regulator-fixed";
		regulator-name = "cam_buck";
		regulator-min-microvolt = <3300000>;
		regulator-max-microvolt = <3300000>;
		gpio = <&pm6150l_gpios 6 GPIO_ACTIVE_HIGH>;
		enable-active-high;
		startup-delay-us = <5000>;
		/* the SLG51000 must be powered for its own I2C to work */
		regulator-always-on;
	};

	/* DMIC supplies, switched by the machine driver (stock audio_ldo1/2) */
	mic1_ldo: regulator-mic1-ldo {
		compatible = "regulator-fixed";
		regulator-name = "mic1_ldo";
		regulator-min-microvolt = <1800000>;
		regulator-max-microvolt = <1800000>;
		gpio = <&pm6150_gpios 6 GPIO_ACTIVE_HIGH>;
		enable-active-high;
	};

	mic2_ldo: regulator-mic2-ldo {
		compatible = "regulator-fixed";
		regulator-name = "mic2_ldo";
		regulator-min-microvolt = <1800000>;
		regulator-max-microvolt = <1800000>;
		gpio = <&pm6150_gpios 7 GPIO_ACTIVE_HIGH>;
		enable-active-high;
	};

	/* Rear camera autofocus actuator supply (downstream camera_ldo) */
	cam_vaf: regulator-cam-vaf {
		compatible = "regulator-fixed";
		regulator-name = "cam_vaf";
		regulator-min-microvolt = <2850000>;
		regulator-max-microvolt = <2850000>;
		gpio = <&pm6150l_gpios 12 GPIO_ACTIVE_HIGH>;
		enable-active-high;
	};
};

&camss {
	vdda-phy-supply = <&vreg_l3c_1p23>;
	vdda-pll-supply = <&vreg_l4a_0p88>;

	status = "okay";

	ports {
		port@0 {
			camss_endpoint0: endpoint {
				clock-lanes = <7>;
				data-lanes = <0 1 2 3>;
				remote-endpoint = <&cam_rear_endpoint>;
			};
		};

		port@2 {
			camss_endpoint2: endpoint {
				clock-lanes = <7>;
				data-lanes = <0 1 2 3>;
				remote-endpoint = <&cam_front_endpoint>;
			};
		};
	};
};

&cci0_i2c0 {
	/* Rear camera: Sony IMX363, CSIPHY0, MCLK0 (as Pixel 3a) */
	rear_cam: camera@1a {
		compatible = "sony,imx363";
		reg = <0x1a>;

		clocks = <&camcc CAMCC_MCLK0_CLK>;
		clock-names = "xvclk";
		clock-frequency = <24000000>;
		assigned-clocks = <&camcc CAMCC_MCLK0_CLK>;
		assigned-clock-rates = <24000000>;

		reset-gpios = <&tlmm 43 GPIO_ACTIVE_LOW>;

		vana-supply = <&slg51000_ldo3>;
		vdig-supply = <&slg51000_ldo6>;
		vif-supply = <&slg51000_ldo7>;

		pinctrl-0 = <&cam_rear_reset_default &cam_mclk0_default>;
		pinctrl-names = "default";

		/*
		 * Verified with captured frames: the raw image must be turned
		 * 90 degrees counter-clockwise for display (the Pixel 3a value,
		 * 90, comes out upside down on the 4a).
		 */
		rotation = <270>;
		orientation = <1>;
		lens-focus = <&rear_cam_actuator>;

		port {
			cam_rear_endpoint: endpoint {
				data-lanes = <0 1 2 3>;
				link-frequencies = /bits/ 64 <321000000 636000000>;
				remote-endpoint = <&camss_endpoint0>;
			};
		};
	};

	/* Autofocus voice coil (stock actuator_rear, VAF from camera_ldo) */
	rear_cam_actuator: actuator@72 {
		compatible = "onnn,lc898219xi";
		reg = <0x72>;
		vdd-supply = <&cam_vaf>;
		vana-supply = <&slg51000_ldo3>;
		vio-supply = <&slg51000_ldo7>;
	};
};

&pm6150l_gpios {
	cam_pmic_en_hog: cam-pmic-en-hog {
		gpio-hog;
		gpios = <1 GPIO_ACTIVE_HIGH>, <5 GPIO_ACTIVE_HIGH>;
		output-low;
		line-name = "slg51000-en";
	};
};

&cci0_i2c1 {
	/* Front camera: Sony IMX355, CSIPHY2, MCLK2 (as Pixel 3a) */
	front_cam: camera@1a {
		compatible = "sony,imx355";
		reg = <0x1a>;

		clocks = <&camcc CAMCC_MCLK2_CLK>;
		/* 24 MHz works, 19.2 MHz has better driver support (Pixel 3a) */
		assigned-clocks = <&camcc CAMCC_MCLK2_CLK>;
		assigned-clock-rates = <19200000>;

		reset-gpios = <&tlmm 68 GPIO_ACTIVE_LOW>;

		avdd-supply = <&slg51000_ldo2>;
		dvdd-supply = <&slg51000_ldo5>;
		dovdd-supply = <&slg51000_ldo7>;

		pinctrl-0 = <&cam_front_reset_default &cam_mclk2_default>;
		pinctrl-names = "default";

		rotation = <270>;
		orientation = <0>;

		port {
			cam_front_endpoint: endpoint {
				data-lanes = <1 2 3 4>;
				link-frequencies = /bits/ 64 <360000000>;
				remote-endpoint = <&camss_endpoint2>;
			};
		};
	};
};
